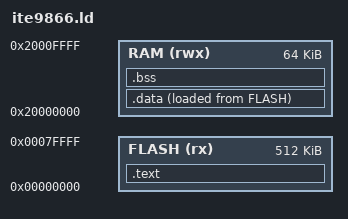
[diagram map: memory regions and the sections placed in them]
/* Minimal linker script for ITE9866 (ARM9, ARMv5TE) metrics test ELF.
 * Memory map is approximate — this ELF is for backend analysis, not execution.
 * Adjust ORIGIN/LENGTH to match your actual ITE9866 memory map. */

ENTRY(main)

MEMORY
{
  FLASH (rx)  : ORIGIN = 0x00000000, LENGTH = 512K
  RAM   (rwx) : ORIGIN = 0x20000000, LENGTH = 64K
}

SECTIONS
{
  .text :
  {
    KEEP(*(.vectors))
    *(.text*)
    *(.rodata*)
  } > FLASH

  .data :
  {
    *(.data*)
  } > RAM AT > FLASH

  .bss (NOLOAD) :
  {
    *(.bss*)
    *(COMMON)
  } > RAM

  /DISCARD/ :
  {
    *(.ARM.exidx*)
    *(.ARM.extab*)
  }
}
